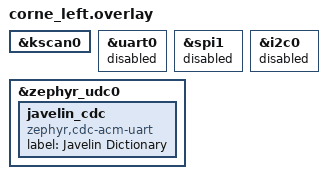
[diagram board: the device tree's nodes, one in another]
#include "../../tools/zen-r4-qspi/qspi.overlay"

&kscan0 {
#include "../zen-r4-left/left-matrix.dtsi"
};

&uart0 { status = "disabled"; };
&spi1 { status = "disabled"; };
&i2c0 { status = "disabled"; };

&zephyr_udc0 {
    javelin_cdc: javelin_cdc {
        compatible = "zephyr,cdc-acm-uart";
        label = "Javelin Dictionary";
    };
};
